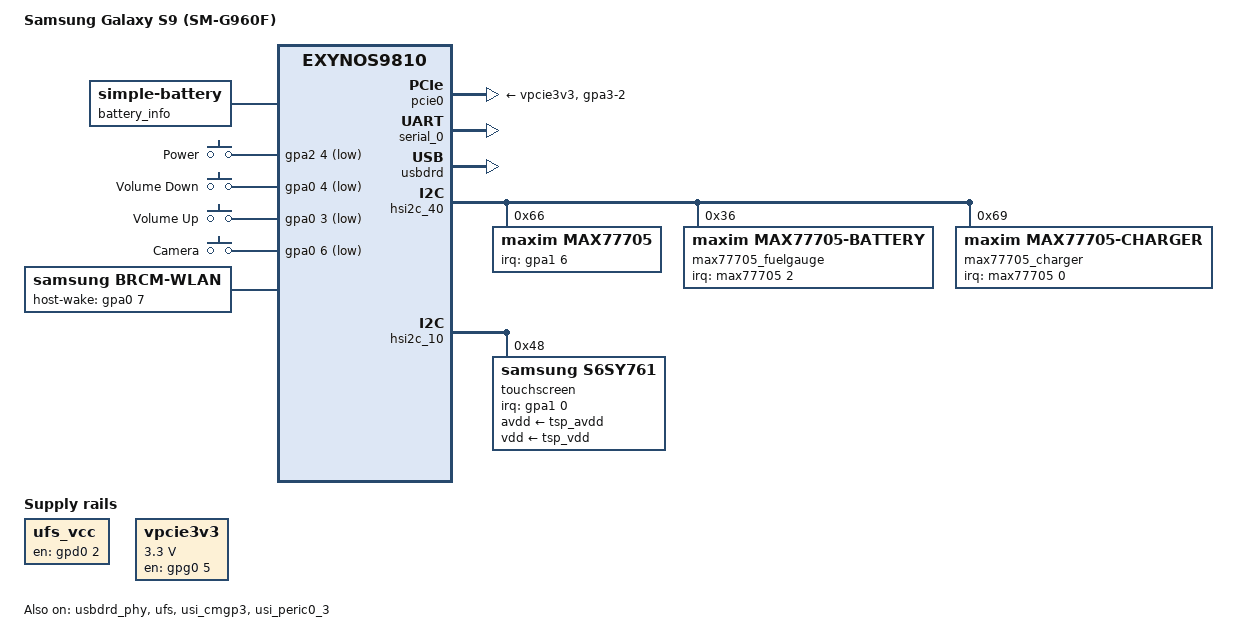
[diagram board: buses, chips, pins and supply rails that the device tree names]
// SPDX-License-Identifier: GPL-2.0 OR BSD-3-Clause
/*
 * Samsung Galaxy S9 (starlte/SM-G960F) device tree source
 *
 * Copyright (c) 2024 Markuss Broks <markuss.broks@gmail.com>
 * Copyright (c) 2024 Maksym Holovach <nergzd@nergzd723.xyz>
 */

/dts-v1/;
#include "exynos9810.dtsi"
#include <dt-bindings/gpio/gpio.h>
#include <dt-bindings/input/input.h>
#include <dt-bindings/mux/maxim,max77705.h>

/ {
	model = "Samsung Galaxy S9 (SM-G960F)";
	compatible = "samsung,starlte", "samsung,exynos9810";
	model_info-chip = <9810>;
	model_info-platform = "android";
	model_info-subtype = "samsung";
	model_info-hw_rev = <26>;
	model_info-hw_rev_end = <255>;
	chassis-type = "handset";

	battery_info: battery {
		compatible = "simple-battery";
		device-chemistry = "lithium-ion";
		voltage-min-design-microvolt = <3200000>;
		voltage-max-design-microvolt = <4350000>;
		charge-full-design-microamp-hours = <3000000>;
		charge-term-current-microamp = <150000>;
		constant-charge-current-max-microamp = <2150000>;
		constant-charge-voltage-max-microvolt = <4350000>;
		over-voltage-threshold-microvolt = <4400000>;
		re-charge-voltage-microvolt = <4280000>;
	};

	chosen {
		#address-cells = <2>;
		#size-cells = <1>;
		ranges;
		bootargs = "earlycon console=ttySAC0,115200n8 \
root=/dev/ram0 rootfstype=tmpfs clk_ignore_unused \
androidboot.hardware=samsungexynos9810 \
androidboot.selinux=permissive androidboot.debug_level=0x4f4c \
firmware_class.path=/vendor/firmware bootconfig";
		stdout-path = "serial0:115200n8";

		framebuffer@cc000000 {
			compatible = "simple-framebuffer";
			reg = <0x0 0xcc000000 (1440 * 2960 * 4)>;
			width = <1440>;
			height = <2960>;
			stride = <(1440 * 4)>;
			format = "a8r8g8b8";
		};
	};

	gpio-keys {
		compatible = "gpio-keys";

		pinctrl-0 = <&key_power &key_voldown &key_volup &key_wink>;
		pinctrl-names = "default";

		power-key {
			label = "Power";
			linux,code = <KEY_POWER>;
			gpios = <&gpa2 4 GPIO_ACTIVE_LOW>;
			wakeup-source;
		};

		voldown-key {
			label = "Volume Down";
			linux,code = <KEY_VOLUMEDOWN>;
			gpios = <&gpa0 4 GPIO_ACTIVE_LOW>;
		};

		volup-key {
			label = "Volume Up";
			linux,code = <KEY_VOLUMEUP>;
			gpios = <&gpa0 3 GPIO_ACTIVE_LOW>;
		};

		/* In stock firmware used for assistant. Map it as a camera button for now */
		wink-key {
			label = "Camera";
			linux,code = <KEY_CAMERA>;
			gpios = <&gpa0 6 GPIO_ACTIVE_LOW>;
		};
	};

	memory@80000000 {
		device_type = "memory";
		reg = <0x0 0x80000000 0x3c800000>,
		      <0x0 0xc0000000 0x20000000>,
		      <0x0 0xe1900000 0x1e700000>,
		      <0x8 0x80000000 0x80000000>;
	};

	reserved-memory {
		#address-cells = <2>;
		#size-cells = <1>;
		ranges;

		memory@80000000 {
			reg = <0x0 0x80000000 0x1000>;
			no-map;
		};

		memory@c0000000 {
			reg = <0x0 0xc0000000 0x80000>;
			no-map;
		};

		cont_splash_mem: framebuffer@cc000000 {
			reg = <0x0 0xcc000000 (1440 * 2960 * 4)>;
			no-map;
		};

		memory@e1900000 {
			reg = <0x0 0xe1900000 0x1e00000>;
			no-map;
		};

		memory@f0000000 {
			reg = <0x0 0xf0000000 0xed10000>;
			no-map;
		};

		ramoops@fed10000 {
			compatible = "ramoops";
			reg = <0x0 0xfed10000 0x8000>;
			record-size = <0x4000>;
			console-size = <0x4000>;
		};

		memory@fed18000 {
			reg = <0x0 0xfed18000 0x12e8000>;
			no-map;
		};
	};

	ufs_vcc: regulator-ufs-vcc {
		compatible = "regulator-fixed";
		regulator-name = "ufs-vcc";
		gpio = <&gpd0 2 GPIO_ACTIVE_HIGH>;
		enable-active-high;
		regulator-boot-on;
	};

	vpcie3v3: regulator-wlan {
		compatible = "regulator-fixed";
		regulator-name = "wlan-reg-on";
		regulator-min-microvolt = <3300000>;
		regulator-max-microvolt = <3300000>;
		gpio = <&gpg0 5 GPIO_ACTIVE_HIGH>;
		enable-active-high;
		startup-delay-us = <200000>;
		pinctrl-0 = <&wlan_reg_on>;
		pinctrl-names = "default";
	};

	wlan {
		compatible = "samsung,brcm-wlan";
		host-wake-gpios = <&gpa0 7 GPIO_ACTIVE_HIGH>;
		pinctrl-0 = <&wlan_host_wake>;
		pinctrl-names = "default";
	};

	s2mps18: pmic {
		compatible = "samsung,s2mps18-regulator";
		acpm-ipc-channel = <2>;

		tsp_vdd: LDO35 {
			regulator-name = "tsp_io";
			regulator-min-microvolt = <1800000>;
			regulator-max-microvolt = <1800000>;
			regulator-boot-on;
		};

		tsp_avdd: LDO43 {
			regulator-name = "tsp_avdd";
			regulator-min-microvolt = <3000000>;
			regulator-max-microvolt = <3000000>;
			regulator-boot-on;
		};
	};

	decon_f: decon_f@16030000 {
		compatible = "samsung,exynos9810-bootfb";
		reg = <0x0 0x16030000 0x1000>,
		      <0x0 0x16021000 0x1000>,
		      <0x0 0x16071000 0x1000>;
		reg-names = "decon", "dpp-g0", "idma-g0";
		interrupts = <GIC_SPI 197 IRQ_TYPE_LEVEL_HIGH>,
			     <GIC_SPI 204 IRQ_TYPE_LEVEL_HIGH>;
		interrupt-names = "idma-g0", "dpp-g0";
		memory-region = <&cont_splash_mem>;
		iommus = <&sysmmu_dpu1>;
		width = <1440>;
		height = <2960>;
		stride = <(1440 * 4)>;
		width-mm = <64>;
		height-mm = <132>;
	};
};

&pcie0 {
	pinctrl-names = "default", "idle";
	pinctrl-0 = <&pcie0_clkreq &pcie0_perst &pcie_wake>;
	pinctrl-1 = <&pcie0_perst &pcie_wake>;
	vpcie3v3-supply = <&vpcie3v3>;
	status = "okay";
};

&oscclk {
	clock-frequency = <26000000>;
};

&serial_0 {
	status = "okay";
};

&usbdrd {
	status = "okay";
};

&usbdrd_dwc3 {
	mux-states = <&max77705_muic MAX77705_MUIC_USB>;
	mux-state-names = "usb";
};

&usbdrd_phy {
	status = "okay";
};

&ufs {
	vcc-supply = <&ufs_vcc>;
	status = "okay";
};

&usi_cmgp3 {
	status = "okay";
};

&hsi2c_40 {
	status = "okay";

	max77705: pmic@66 {
		compatible = "maxim,max77705";
		reg = <0x66>;
		interrupt-parent = <&gpa1>;
		interrupts = <6 IRQ_TYPE_LEVEL_LOW>;
		interrupt-controller;
		#interrupt-cells = <1>;
		pinctrl-0 = <&max77705_irq>;
		pinctrl-names = "default";

		max77705_muic: usb-mux {
			compatible = "maxim,max77705-muic";
			#mux-state-cells = <1>;
		};
	};

	max77705_fuelgauge: fuel-gauge@36 {
		compatible = "maxim,max77705-battery";
		reg = <0x36>;
		interrupt-parent = <&max77705>;
		interrupts = <2>;
		power-supplies = <&max77705_charger>;
		shunt-resistor-micro-ohms = <5000>;
		maxim,cold-temp = <0>;
		maxim,over-heat-temp = <500>;
		maxim,dead-volt = <3200>;
		maxim,over-volt = <4400>;
	};

	max77705_charger: charger@69 {
		compatible = "maxim,max77705-charger";
		reg = <0x69>;
		interrupt-parent = <&max77705>;
		interrupts = <0>;
		monitored-battery = <&battery_info>;
		maxim,enable-watchdog;
		maxim,b2s-overcurrent-microamp = <5600000>;
		maxim,input-current-max-microamp = <3000000>;
		maxim,default-input-current-microamp = <1800000>;
		maxim,default-charge-current-microamp = <2100000>;
		maxim,charging-current-table =
			<2 500000 500000>,
			<19 500000 500000>,
			<21 500000 500000>,
			<22 500000 500000>,
			<23 500000 500000>,
			<30 500000 500000>,
			<25 1000000 1000000>,
			<31 1000000 1000000>,
			<5 1500000 1500000>,
			<32 1500000 1500000>,
			<6 1650000 2150000>,
			<7 1650000 2150000>,
			<8 1650000 2150000>,
			<9 1650000 2150000>,
			<10 900000 1200000>,
			<12 900000 1200000>,
			<15 900000 1200000>,
			<27 900000 1200000>,
			<33 900000 1200000>,
			<13 700000 1200000>,
			<24 1000000 450000>,
			<26 2000000 1800000>,
			<11 650000 1200000>,
			<14 650000 1200000>,
			<16 650000 1200000>,
			<28 650000 1200000>,
			<29 500000 1200000>,
			<1 475000 550000>,
			<4 475000 550000>;
	};
};

&usi_peric0_3 {
	status = "okay";
};

&hsi2c_10 {
	status = "okay";
	samsung,stop-after-trans;

	touchscreen@48 {
		compatible = "samsung,s6sy761";
		reg = <0x48>;
		interrupt-parent = <&gpa1>;
		interrupts = <0 IRQ_TYPE_LEVEL_LOW>;
		pinctrl-0 = <&tsp_irq>;
		pinctrl-names = "default";
		avdd-supply = <&tsp_avdd>;
		vdd-supply = <&tsp_vdd>;
		touchscreen-size-x = <4096>;
		touchscreen-size-y = <4096>;
	};
};

&pinctrl_alive {
	key_power: key-power-pins {
		samsung,pins = "gpa2-4";
		samsung,pin-function = <EXYNOS_PIN_FUNC_EINT>;
		samsung,pin-pud = <EXYNOS_PIN_PULL_UP>;
		samsung,pin-drv = <EXYNOS5420_PIN_DRV_LV1>;
	};

	key_voldown: key-voldown-pins {
		samsung,pins = "gpa0-4";
		samsung,pin-function = <EXYNOS_PIN_FUNC_EINT>;
		samsung,pin-pud = <EXYNOS_PIN_PULL_UP>;
		samsung,pin-drv = <EXYNOS5420_PIN_DRV_LV1>;
	};

	key_volup: key-volup-pins {
		samsung,pins = "gpa0-3";
		samsung,pin-function = <EXYNOS_PIN_FUNC_EINT>;
		samsung,pin-pud = <EXYNOS_PIN_PULL_UP>;
		samsung,pin-drv = <EXYNOS5420_PIN_DRV_LV1>;
	};

	key_wink: key-wink-pins {
		samsung,pins = "gpa0-6";
		samsung,pin-function = <EXYNOS_PIN_FUNC_EINT>;
		samsung,pin-pud = <EXYNOS_PIN_PULL_UP>;
		samsung,pin-drv = <EXYNOS5420_PIN_DRV_LV1>;
	};

	max77705_irq: max77705-irq-pins {
		samsung,pins = "gpa1-6";
		samsung,pin-function = <EXYNOS_PIN_FUNC_EINT>;
		samsung,pin-pud = <EXYNOS_PIN_PULL_NONE>;
		samsung,pin-drv = <EXYNOS5420_PIN_DRV_LV1>;
	};

	tsp_irq: tsp-irq-pins {
		samsung,pins = "gpa1-0";
		samsung,pin-function = <EXYNOS_PIN_FUNC_EINT>;
		samsung,pin-pud = <EXYNOS_PIN_PULL_NONE>;
		samsung,pin-drv = <EXYNOS5420_PIN_DRV_LV1>;
	};

	pcie_wake: pcie-wake-pins {
		samsung,pins = "gpa3-2";
		samsung,pin-function = <EXYNOS_PIN_FUNC_INPUT>;
		samsung,pin-pud = <EXYNOS_PIN_PULL_NONE>;
	};

	wlan_host_wake: wlan-host-wake-pins {
		samsung,pins = "gpa0-7";
		samsung,pin-function = <EXYNOS_PIN_FUNC_EINT>;
		samsung,pin-pud = <EXYNOS_PIN_PULL_DOWN>;
		samsung,pin-drv = <EXYNOS5420_PIN_DRV_LV1>;
		samsung,pin-con-pdn = <EXYNOS_PIN_PDN_PREV>;
		samsung,pin-pud-pdn = <EXYNOS_PIN_PULL_DOWN>;
	};
};

&pinctrl_peric0 {
	wlan_reg_on: wlan-reg-on-pins {
		samsung,pins = "gpg0-5";
		samsung,pin-function = <EXYNOS_PIN_FUNC_OUTPUT>;
		samsung,pin-pud = <EXYNOS_PIN_PULL_NONE>;
		samsung,pin-drv = <EXYNOS7_PIN_DRV_LV4>;
		samsung,pin-con-pdn = <EXYNOS_PIN_PDN_PREV>;
	};
};
